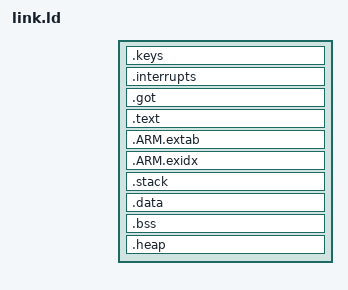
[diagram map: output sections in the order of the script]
/*
 *    Code Released under MIT License
 *
 *    STM32 port
 *    Copyright (c) 2021 CSEM SA
 *
 *    Interrupt fork
 *    Copyright (c) 2019 Memfault, Inc.
 * 
 *    Original Jekyll Template
 *    Copyright (c) 2015 Jacopo Rabolini
 * 
 *    Permission is hereby granted, free of charge, to any person obtaining a 
 *    copy of this software and associated documentation files (the "Software"), 
 *    to deal in the Software without restriction, including without limitation 
 *    the rights to use, copy, modify, merge, publish, distribute, sublicense, 
 *    and/or sell copies of the Software, and to permit persons to whom the 
 *    Software is furnished to do so, subject to the following conditions:
 * 
 *    The above copyright notice and this permission notice shall be included 
 *    in all copies or substantial portions of the Software.
 * 
 *    THE SOFTWARE IS PROVIDED "AS IS", WITHOUT WARRANTY OF ANY KIND, EXPRESS 
 *    OR IMPLIED, INCLUDING BUT NOT LIMITED TO THE WARRANTIES OF MERCHANTABILITY, 
 *    FITNESS FOR A PARTICULAR PURPOSE AND NONINFRINGEMENT. IN NO EVENT SHALL 
 *    THE AUTHORS OR COPYRIGHT HOLDERS BE LIABLE FOR ANY CLAIM, DAMAGES OR OTHER 
 *    LIABILITY, WHETHER IN AN ACTION OF CONTRACT, TORT OR OTHERWISE, ARISING FROM, 
 *    OUT OF OR IN CONNECTION WITH THE SOFTWARE OR THE USE OR OTHER DEALINGS IN 
 *    THE SOFTWARE.
 */

INCLUDE memory-sections.ld

STACK_SIZE = 0x2000;

/* Section Definitions */
SECTIONS
{
	.keys :
	{
		KEEP(*(.secure_storage .secure_storage.*))
	} > BOOTLOADER_STORAGE

    .interrupts :
    {
        KEEP(*(.isr_vector .isr_vector.*))
    } > BOOTLOADER_CODE

    .got :
    {
        KEEP(*(.got .got.*))
    } > BOOTLOADER_CODE

    .text :
    {
        *(.text .text.* .gnu.linkonce.t.*)
        *(.glue_7t) *(.glue_7)
        *(.rodata .rodata* .gnu.linkonce.r.*)
    } > BOOTLOADER_CODE

    .ARM.extab :
    {
        *(.ARM.extab* .gnu.linkonce.armextab.*)
    } > BOOTLOADER_CODE

    .ARM.exidx :
    {
        *(.ARM.exidx* .gnu.linkonce.armexidx.*)
    } > BOOTLOADER_CODE

    . = ALIGN(4);
    _etext = .;
    _sidata = .;


    /* stack section */
    .stack (NOLOAD):
    {
        . = ALIGN(8);
        _sstack = .;
        . = . + STACK_SIZE;
        . = ALIGN(8);
        _estack = .;
    } > RAM

    .data : AT (_etext)
    {
        . = ALIGN(4);
        _sdata = .;
        *(ram_func )
        *(.data .data.*)
        . = ALIGN(4);
        _edata = . ;
    } > RAM

    /* .bss section which is used for uninitialized data */
    .bss (NOLOAD) :
    {
        _sbss = . ;
        __bss_start__ = _sbss;
        *(.bss.s_graphics_buf)
        *(.bss.s_registered_handler)
        *(.bss .bss.*)
        *(COMMON)
        . = ALIGN(4);
        _ebss = . ;
        __bss_end__ = _ebss;
    } > RAM

    .heap (COPY):
    {
        . = ALIGN(4);
        PROVIDE ( end = . );
        PROVIDE ( _end = . );
        PROVIDE ( __end__ = . );

        *(.heap*)
        __HeapLimit = .;
        . = ALIGN(4);
    } > RAM

    . = ALIGN(4);
    _end = . ;
}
